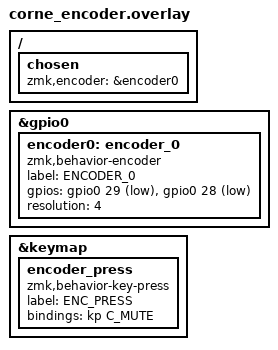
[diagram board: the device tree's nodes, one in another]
/ {
    chosen {
        zmk,encoder = &encoder0;
    };
};

&gpio0 {
    encoder0: encoder_0 {
        compatible = "zmk,behavior-encoder";
        label = "ENCODER_0";

        gpios = <&gpio0 29 GPIO_ACTIVE_LOW>,
                <&gpio0 28 GPIO_ACTIVE_LOW>;

        resolution = <4>;
    };
};

/* Encoder press */
&keymap {
    encoder_press {
        compatible = "zmk,behavior-key-press";
        label = "ENC_PRESS";
        #binding-cells = <0>;
        bindings = <&kp C_MUTE>;
    };
};
